# PAC55XX register map
Vendor: Qorvo, Inc.; Series: PAC55XX; File version: 1.0
CPU: CM4 r0p1, little endian, MPU, FPU, vendor SysTick, 3 interrupt priority bits
Registers are 32-bit, read-write, reset 0x0 unless marked. A register's access mark holds for its fields unless they carry their own. Offsets are from the block's base; [hi:lo] are bit positions; {n}, {i} and the like mark numbered series.

## GPTIMERA — General Purpose Timer A
Base 0x400B0000
Same registers: GPTIMERB 0x400C0000
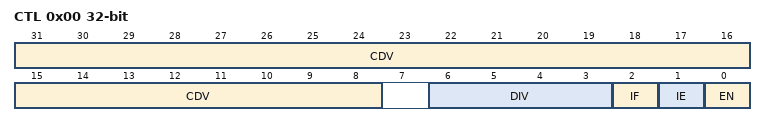
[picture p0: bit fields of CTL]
0x00 CTL — GPTimer Control
  [31:8] CDV — Count-down value
  [6:3] DIV — Clock Divider
    0=PCLK1; 1=PCLK2; 2=PCLK4; 3=PCLK8; 4=PCLK16; 5=PCLK32; 6=PCLK64; 7=PCLK128; 8=PCLK256; 9=PCLK512; 10=PCLK1024; 11=PCLK2048; 12=PCLK4096; 13=PCLK8192; 14=PCLK16384; 15=PCLK32768
  [2] IF — Interrupt Flag
  [1] IE — Interrupt Enable
  [0] EN — Enable
0x04 CTR — GPTimer Counter
  [23:0] CTR — Counter value

## MEMCTL — Memory Controller
Base 0x400D0000
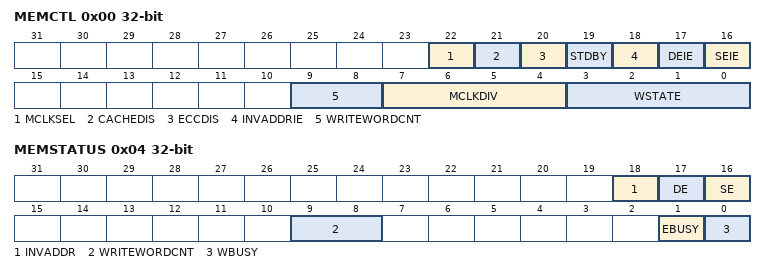
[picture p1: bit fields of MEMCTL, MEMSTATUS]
0x00 MEMCTL — Memory Controller Configuration
  [22] MCLKSEL — MCLK Mux Select
    0=ROSCCLK (ROSCCLK as MCLK); 1=MCLK (HCLK/MCLKDIV as MCLK)
  [21] CACHEDIS — FLASH Read Cache Disable
  [20] ECCDIS — SRAM ECC Disable
  [19] STDBY — FLASH Standby Mode
  [18] INVADDRIE — Invalid Memory Address Access Interrupt Enable
  [17] DEIE — ECC Dual bit Error Interrupt Enable
  [16] SEIE — ECC Single bit Error Interrupt Enable
  [9:8] WRITEWORDCNT — Write Word Data Count
  [7:4] MCLKDIV — MCLK Divider
    {v}=DIV{v+1} (/{v+1}) (v=0..15)
  [3:0] WSTATE — FLASH Access Wait States
0x04 MEMSTATUS — Memory Controller Status
  [18] INVADDR — Invalid Memory Address Access Flag
  [17] DE — ECC Dual bit Error Detection Flag
  [16] SE — ECC Single bit Error Detection Flag
  [9:8] WRITEWORDCNT — Number of bytes written to FLASH for the write data buffer
    0=BYTES4 (4 bytes); 1=BYTES8 (8 bytes); 2=BYTES12 (12 bytes); 3=BYTES16 (16 bytes)
  [1] EBUSY — FLASH Erase Busy
  [0] WBUSY — FLASH Write Busy
0x08 FLASHLOCK — FLASH Lock Access
  [31:0] FLASHLOCK — Flash Lock Value for Memory Controller Operations
    0=RESET (Reset value); 0x43DF140A=ALLOW_WRITE_ERASE_FLASH (Allow write and erase operations); 0x79B4F762=ALLOW_WRITE_INFO2SWDFUSE (Allow write to INFO2.SWDFUSE register); 0xD513B490=ALLOW_WRITE_MEMCTL (Allow write to MEMCTRL register)
0x0C FLASHPAGE
  [6:0] PAGE — Flash page selection
0x10 SWDUNLOCK
  [31:0] KEY_SWDUNLOCK wo — Key for SWD unlock
0x20 FLASHERASE
  [31:0] KEY — Key for erase operations
    0x8C799CA7=PAGE_ERASE; 0x9EE76C9=MASS_PAGE_ERASE; 0x1266FF45=INFO_3_ERASE

## WWDT — Windowed Watchdog Timer
Base 0x400D0800
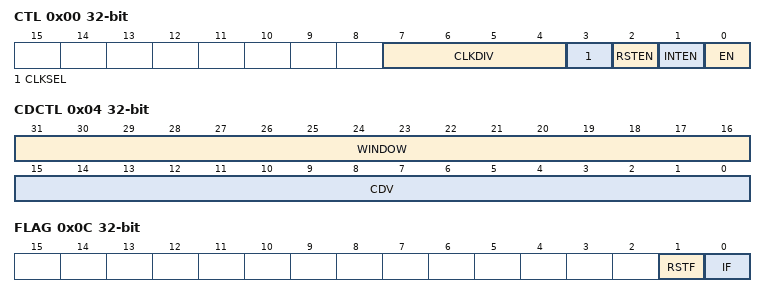
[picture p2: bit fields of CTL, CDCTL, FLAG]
0x00 CTL — WWDT Control
  [7:4] CLKDIV — WWDT input clock divider
    0=DIV1 (/1); 1=DIV2 (/2); 2=DIV4 (/4); 3=DIV8 (/8); 4=DIV16 (/16); 5=DIV32 (/32); 6=DIV64 (/64); 7=DIV128 (/128); 8=DIV256 (/256); 9=DIV512 (/512); 10=DIV1024 (/1024); 11=DIV2048 (/2048); 12=DIV4096 (/4096); 13=DIV8192 (/8192); 14=DIV16384 (/16384); 15=DIV32768 (/32768)
  [3] CLKSEL — WWDT input clock source
    0=FRCLK (FRCLK as WWDT clock); 1=ROSCCLK (ROSCCLK as WWDT clock)
  [2] RSTEN — Enable WWDT POR reset
  [1] INTEN — Enable WWDT interrupt
  [0] EN — Enable WWDT
0x04 CDCTL — WWDT Load Counter Value
  [31:16] WINDOW — WWDT window value
  [15:0] CDV — WWDT count-down value
0x08 CTR ro — WWDT Counter
  [15:0] CNT — WWDT counter value
0x0C FLAG — WWDT Interrupt Flag
  [1] RSTF — WWDT reset flag
  [0] IF — WWDT interrupt flag
0x10 CLEAR wo — WWDT Interrupt Clear
  [31:0] VALUE — WWDT clear
0x14 LOCK — WWDT Lock
  [31:0] VALUE — WWDT lock
    0x55AA6698=READ_ONLY (WWDT registers are read-only); 0x55AA6699=ALLOW_WRITE (WWDT registers available for write)

## RTC — Real-Time Clock (RTC) with Calendar
Base 0x400D0C00
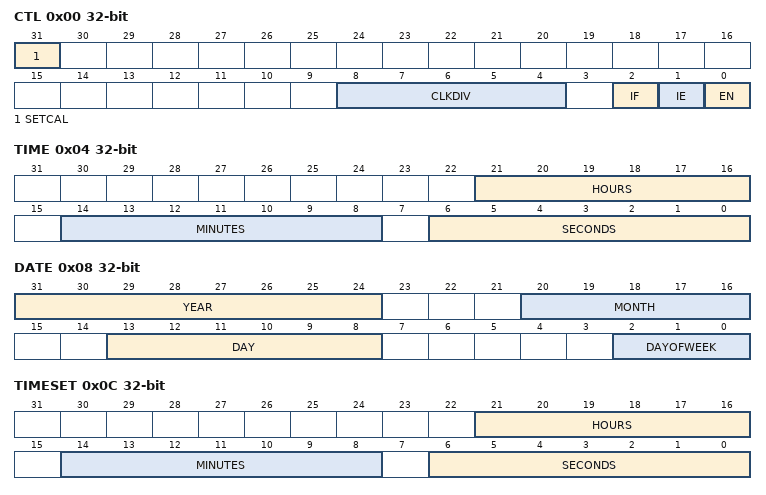
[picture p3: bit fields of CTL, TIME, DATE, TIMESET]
0x00 CTL — RTC Control
  [31] SETCAL — Set the internal TIME/DATA with TIMESET/DATESET values
  [8:4] CLKDIV — Clock divider for the RTC input clock (FRCLK)
    {v}=DIV{v+1} (FRCLK/{v+1}) (v=0..31)
  [2] IF — Alarm match interrupt flag
  [1] IE — Alarm match interrupt enable
  [0] EN — Enable RTC
0x04 TIME — RTC Time
  [21:16] HOURS, [14:8] MINUTES, [6:0] SECONDS
0x08 DATE — RTC Date
  [31:24] YEAR, [20:16] MONTH, [13:8] DAY, [2:0] DAYOFWEEK
0x0C TIMESET — RTC Time Setting
  [21:16] HOURS, [14:8] MINUTES, [6:0] SECONDS
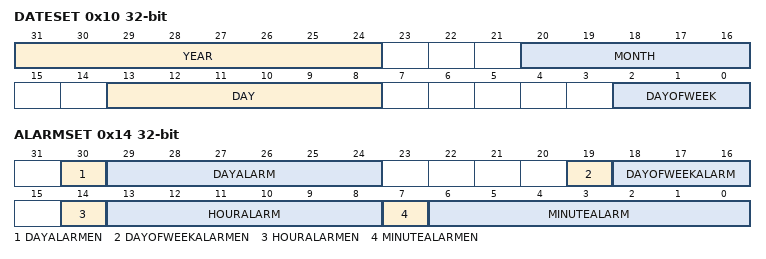
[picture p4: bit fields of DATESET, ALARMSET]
0x10 DATESET — RTC Date Setting
  [31:24] YEAR, [20:16] MONTH, [13:8] DAY, [2:0] DAYOFWEEK
0x14 ALARMSET — RTC Alarm Setting
  [30] DAYALARMEN — Day alarm enable
  [29:24] DAYALARM
  [19] DAYOFWEEKALARMEN — Day of week alarm enable
  [18:16] DAYOFWEEKALARM
  [14] HOURALARMEN — Hour alarm enable
  [13:8] HOURALARM
  [7] MINUTEALARMEN — Minute alarm enable
  [6:0] MINUTEALARM

## CRC — Cyclic Redundancy Check
Base 0x400D1000
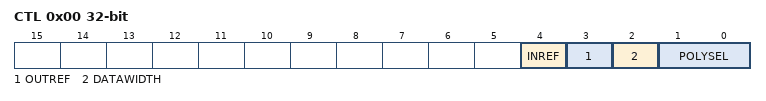
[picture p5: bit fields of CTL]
0x00 CTL — CRC Control
  [4] INREF — Reflect DATAIN input data to CRC engine
  [3] OUTREF — Reflect DATAOUT output data from CRC engine
  [2] DATAWIDTH — CRC Data Width
    0=BITS32 (32 bits); 1=BITS8 (8 bits)
  [1:0] POLYSEL — CRC Polynomial Select
    0=CRC_16_CCITT; 1=CRC_16_IBM; 2=CRC_8_DALLAS_MAXIM
0x04 DATAIN — CRC Data Input
0x08 SEED — CRC Seed Value
  [15:0] CRCSEED
0x0C OUT — CRC Data Output
  [15:0] CRCOUT ro — CRC data output value

## GPIOA — General Purpose Input/Output A
Base 0x400D1400
Same registers: GPIOB 0x400D1800, GPIOC 0x400D1C00, GPIOD 0x400D2000, GPIOE 0x400D2400, GPIOF 0x400D2800, GPIOG 0x400D2C00
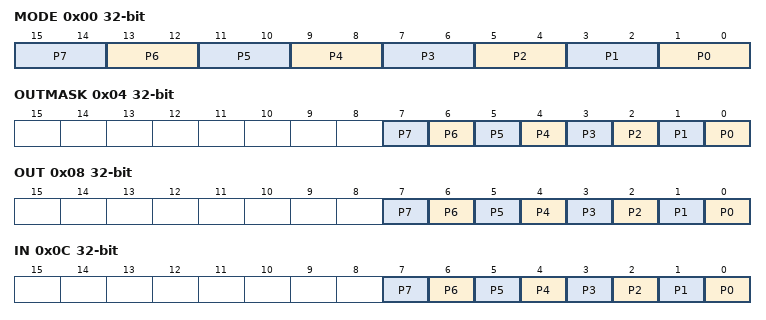
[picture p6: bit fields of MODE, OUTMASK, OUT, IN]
0x00 MODE — GPIO Pin Mode Select
  [all] fields
    0=ANALOG (Analog input); 1=PUSH_PULL_OUTPUT; 2=OPEN_DRAIN_OUTPUT; 3=HIGH_IMPEDANCE_INPUT
  [2n+1:2n] P{n} (n=0..7) — Pin {n} mode
0x04 OUTMASK — GPIO Data Output Write Mask
  [n] P{n} (n=0..7) — Pin {n} output data mask
0x08 OUT — GPIO Data Output Value
  [n] P{n} (n=0..7) — Pin {n} output data value
0x0C IN — GPIO Data Input Value
  [n] P{n} (n=0..7) — Pin {n} input data value
0x10 INTEN — GPIO Interrupt Enable
0x14 INTFLAGRAW — GPIO Interrupt Flag Raw
0x18 INTFLAGMASKED — GPIO Interrupt Flag Masked
0x1C INTCLEAR — GPIO Interrupt Clear
0x20 INTTYPE — GPIO Interrupt Type
0x24 INTVALUE — GPIO Interrupt Value
0x28 INTEDGEBOTH — GPIO Interrupt Edge Both
0x2C DEBOUNCE — GPIO De-bounce Filter
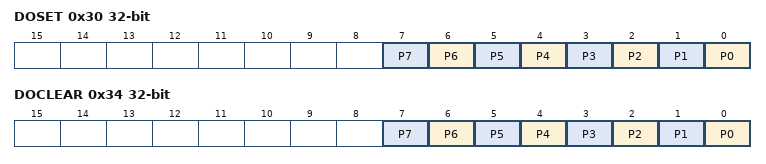
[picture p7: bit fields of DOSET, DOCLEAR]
0x30 DOSET — GPIO Data Output Set
  [n] P{n} (n=0..7) — Pin {n} data output set
0x34 DOCLEAR — GPIO Data Output Clear
  [n] P{n} (n=0..7) — Pin {n} data output clear
